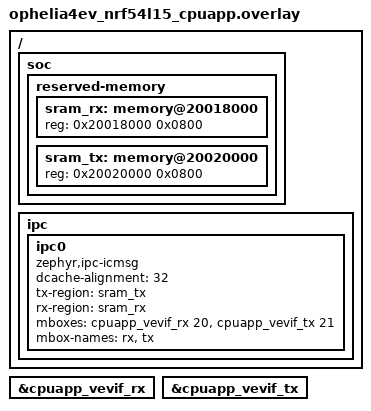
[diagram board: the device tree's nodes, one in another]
/*
 * Copyright (c) 2025 Würth Elektronik eiSos GmbH & Co. KG
 *
 * SPDX-License-Identifier: Apache-2.0
 */

/ {
	soc {
		reserved-memory {
			#address-cells = <1>;
			#size-cells = <1>;

			sram_rx: memory@20018000 {
				reg = <0x20018000 0x0800>;
			};

			sram_tx: memory@20020000 {
				reg = <0x20020000 0x0800>;
			};
		};
	};

	ipc {
		ipc0: ipc0 {
			compatible = "zephyr,ipc-icmsg";
			dcache-alignment = <32>;
			tx-region = <&sram_tx>;
			rx-region = <&sram_rx>;
			mboxes = <&cpuapp_vevif_rx 20>, <&cpuapp_vevif_tx 21>;
			mbox-names = "rx", "tx";
			status = "okay";
		};
	};
};

&cpuapp_vevif_rx {
	status = "okay";
};

&cpuapp_vevif_tx {
	status = "okay";
};
